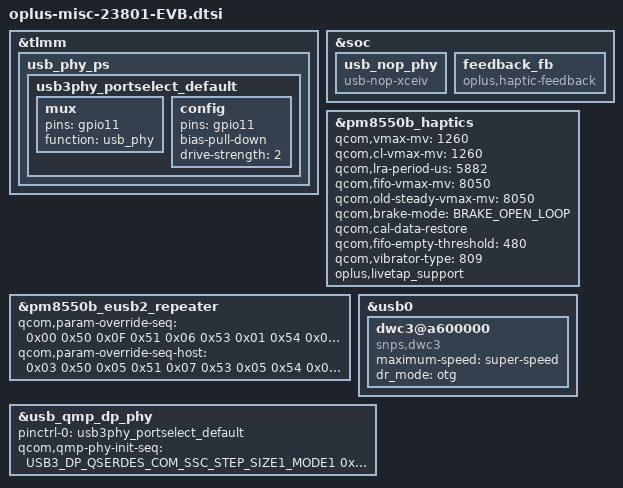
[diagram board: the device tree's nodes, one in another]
#include <dt-bindings/phy/qcom,usb3-4nm-qmp-combo.h>

&tlmm {
	usb_phy_ps: usb_phy_ps {
		usb3phy_portselect_default: usb3phy_portselect_default {
			mux {
				pins = "gpio11";
				function = "usb_phy";
			};

			config {
				pins = "gpio11";
				bias-pull-down;
				drive-strength = <2>;
			};
		};
	};
};

&soc {
	usb_nop_phy: usb_nop_phy {
		compatible = "usb-nop-xceiv";
	};
};

&pm8550b_haptics {
	qcom,vmax-mv = <1260>;
	qcom,cl-vmax-mv = <1260>;
	qcom,lra-period-us = <5882>;
	qcom,fifo-vmax-mv = <8050>;
	qcom,old-steady-vmax-mv = <8050>;
	qcom,brake-mode = <BRAKE_OPEN_LOOP>;
	qcom,cal-data-restore;
	qcom,fifo-empty-threshold = <480>;
	qcom,vibrator-type = <809>;//0809
	oplus,livetap_support;
};

&pm8550b_eusb2_repeater {
	qcom,param-override-seq = <0x00 0x50 0x0F 0x51 0x06 0x53 0x01 0x54
			0x03 0x55 0x00 0x56 0x07 0x57 0x2 0x58 0x3 0x59 0x1 0x5A 0x2 0x5B>;
	qcom,param-override-seq-host = <0x03 0x50 0x05 0x51 0x07 0x53 0x05 0x54
			0x01 0x55 0x00 0x56 0x02 0x57 0x2 0x58 0x3 0x59 0x1 0x5A 0x2 0x5B>;
};

&usb0 {
	dwc3@a600000 {
		compatible = "snps,dwc3";
		maximum-speed = "super-speed";
		dr_mode = "otg";
	};
};

&usb_qmp_dp_phy {
	pinctrl-names = "default";
	pinctrl-0 = <&usb3phy_portselect_default>;
	qcom,qmp-phy-init-seq =
		/* <reg_offset, value> */
		<USB3_DP_QSERDES_COM_SSC_STEP_SIZE1_MODE1 0xC0
		USB3_DP_QSERDES_COM_SSC_STEP_SIZE2_MODE1 0x01
		USB3_DP_QSERDES_COM_CP_CTRL_MODE1 0x02
		0x220c 0x3F
		0x260c 0x3F
		USB3_DP_QSERDES_COM_PLL_RCTRL_MODE1 0x16
		USB3_DP_QSERDES_COM_PLL_CCTRL_MODE1 0x36
		USB3_DP_QSERDES_COM_CORECLK_DIV_MODE1 0x04
		USB3_DP_QSERDES_COM_LOCK_CMP1_MODE1 0x16
		USB3_DP_QSERDES_COM_LOCK_CMP2_MODE1 0x41
		USB3_DP_QSERDES_COM_DEC_START_MODE1 0x41
		USB3_DP_QSERDES_COM_DEC_START_MSB_MODE1 0x00
		USB3_DP_QSERDES_COM_DIV_FRAC_START1_MODE1 0x55
		USB3_DP_QSERDES_COM_DIV_FRAC_START2_MODE1 0x75
		USB3_DP_QSERDES_COM_DIV_FRAC_START3_MODE1 0x01
		USB3_DP_QSERDES_COM_HSCLK_SEL_1 0x01
		USB3_DP_QSERDES_COM_VCO_TUNE1_MODE1 0x25
		USB3_DP_QSERDES_COM_VCO_TUNE2_MODE1 0x02
		USB3_DP_QSERDES_COM_BIN_VCOCAL_CMP_CODE1_MODE1 0x5C
		USB3_DP_QSERDES_COM_BIN_VCOCAL_CMP_CODE2_MODE1 0x0F
		USB3_DP_QSERDES_COM_BIN_VCOCAL_CMP_CODE1_MODE0 0x5C
		USB3_DP_QSERDES_COM_BIN_VCOCAL_CMP_CODE2_MODE0 0x0F
		USB3_DP_QSERDES_COM_SSC_STEP_SIZE1_MODE0 0xC0
		USB3_DP_QSERDES_COM_SSC_STEP_SIZE2_MODE0 0x01
		USB3_DP_QSERDES_COM_CP_CTRL_MODE0 0x02
		USB3_DP_QSERDES_COM_PLL_RCTRL_MODE0 0x16
		USB3_DP_QSERDES_COM_PLL_CCTRL_MODE0 0x36
		USB3_DP_QSERDES_COM_LOCK_CMP1_MODE0 0x08
		USB3_DP_QSERDES_COM_LOCK_CMP2_MODE0 0x1A
		USB3_DP_QSERDES_COM_DEC_START_MODE0 0x41
		USB3_DP_QSERDES_COM_DEC_START_MSB_MODE0 0x00
		USB3_DP_QSERDES_COM_DIV_FRAC_START1_MODE0 0x55
		USB3_DP_QSERDES_COM_DIV_FRAC_START2_MODE0 0x75
		USB3_DP_QSERDES_COM_DIV_FRAC_START3_MODE0 0x01
		USB3_DP_QSERDES_COM_VCO_TUNE1_MODE0 0x25
		USB3_DP_QSERDES_COM_VCO_TUNE2_MODE0 0x02
		USB3_DP_QSERDES_COM_BG_TIMER 0x0A
		USB3_DP_QSERDES_COM_SSC_EN_CENTER 0x01
		USB3_DP_QSERDES_COM_SSC_PER1 0x62
		USB3_DP_QSERDES_COM_SSC_PER2 0x02
		USB3_DP_QSERDES_COM_SYSCLK_BUF_ENABLE 0x0C
		USB3_DP_QSERDES_COM_SYSCLK_EN_SEL 0x1A
		USB3_DP_QSERDES_COM_LOCK_CMP_CFG 0x14
		USB3_DP_QSERDES_COM_VCO_TUNE_MAP 0x04
		USB3_DP_QSERDES_COM_CORE_CLK_EN 0x20
		USB3_DP_QSERDES_COM_CMN_CONFIG_1 0x16
		USB3_DP_QSERDES_COM_AUTO_GAIN_ADJ_CTRL_1 0xB6
		USB3_DP_QSERDES_COM_AUTO_GAIN_ADJ_CTRL_2 0x4B
		USB3_DP_QSERDES_COM_AUTO_GAIN_ADJ_CTRL_3 0x37
		USB3_DP_QSERDES_COM_ADDITIONAL_MISC 0x0C
		USB3_DP_QSERDES_TXA_RES_CODE_LANE_TX 0x00
		USB3_DP_QSERDES_TXA_RES_CODE_LANE_RX 0x00
		USB3_DP_QSERDES_TXA_RES_CODE_LANE_OFFSET_TX 0x1F
		USB3_DP_QSERDES_TXA_RES_CODE_LANE_OFFSET_RX 0x09
		USB3_DP_QSERDES_TXA_LANE_MODE_1 0xF5
		USB3_DP_QSERDES_TXA_LANE_MODE_3 0x3F
		USB3_DP_QSERDES_TXA_LANE_MODE_4 0x3F
		USB3_DP_QSERDES_TXA_LANE_MODE_5 0x5F
		USB3_DP_QSERDES_TXA_RCV_DETECT_LVL_2 0x12
		USB3_DP_QSERDES_TXA_PI_QEC_CTRL 0x21
		USB3_DP_QSERDES_RXA_UCDR_FO_GAIN 0x0A
		USB3_DP_QSERDES_RXA_UCDR_SO_GAIN 0x06
		USB3_DP_QSERDES_RXA_UCDR_FASTLOCK_FO_GAIN 0x2F
		USB3_DP_QSERDES_RXA_UCDR_SO_SATURATION_AND_ENABLE 0x7F
		USB3_DP_QSERDES_RXA_UCDR_FASTLOCK_COUNT_LOW 0xFF
		USB3_DP_QSERDES_RXA_UCDR_FASTLOCK_COUNT_HIGH 0x0F
		USB3_DP_QSERDES_RXA_UCDR_PI_CONTROLS 0x99
		USB3_DP_QSERDES_RXA_UCDR_SB2_THRESH1 0x08
		USB3_DP_QSERDES_RXA_UCDR_SB2_THRESH2 0x08
		USB3_DP_QSERDES_RXA_UCDR_SB2_GAIN1 0x00
		USB3_DP_QSERDES_RXA_UCDR_SB2_GAIN2 0x0A
		USB3_DP_QSERDES_RXA_AUX_DATA_TCOARSE_TFINE 0xA0
		USB3_DP_QSERDES_RXA_VGA_CAL_CNTRL1 0x54
		USB3_DP_QSERDES_RXA_VGA_CAL_CNTRL2 0x0F
		USB3_DP_QSERDES_RXA_GM_CAL 0x13
		USB3_DP_QSERDES_RXA_RX_EQU_ADAPTOR_CNTRL2 0x0F
		USB3_DP_QSERDES_RXA_RX_EQU_ADAPTOR_CNTRL3 0x4A
		USB3_DP_QSERDES_RXA_RX_EQU_ADAPTOR_CNTRL4 0x0A
		USB3_DP_QSERDES_RXA_RX_IDAC_TSETTLE_LOW 0x07
		USB3_DP_QSERDES_RXA_RX_IDAC_TSETTLE_HIGH 0x00
		USB3_DP_QSERDES_RXA_RX_EQ_OFFSET_ADAPTOR_CNTRL1 0x47
		USB3_DP_QSERDES_RXA_SIGDET_CNTRL 0x04
		USB3_DP_QSERDES_RXA_SIGDET_DEGLITCH_CNTRL 0x0E
		USB3_DP_QSERDES_RXA_RX_MODE_00_LOW 0x3F
		USB3_DP_QSERDES_RXA_RX_MODE_00_HIGH 0xBF
		USB3_DP_QSERDES_RXA_RX_MODE_00_HIGH2 0xFF
		USB3_DP_QSERDES_RXA_RX_MODE_00_HIGH3 0xDF
		USB3_DP_QSERDES_RXA_RX_MODE_00_HIGH4 0xED
		USB3_DP_QSERDES_RXA_RX_MODE_01_LOW 0xDC
		USB3_DP_QSERDES_RXA_RX_MODE_01_HIGH 0x5C
		USB3_DP_QSERDES_RXA_RX_MODE_01_HIGH2 0x9C
		USB3_DP_QSERDES_RXA_RX_MODE_01_HIGH3 0x1D
		USB3_DP_QSERDES_RXA_RX_MODE_01_HIGH4 0x09
		USB3_DP_QSERDES_RXA_DFE_EN_TIMER 0x04
		USB3_DP_QSERDES_RXA_DFE_CTLE_POST_CAL_OFFSET 0x38
		USB3_DP_QSERDES_RXA_DCC_CTRL1 0x0C
		USB3_DP_QSERDES_RXA_VTH_CODE 0x10
		USB3_DP_QSERDES_RXA_SIGDET_CAL_CTRL1 0x14
		USB3_DP_QSERDES_RXA_SIGDET_CAL_TRIM 0x08
		USB3_DP_QSERDES_TXB_RES_CODE_LANE_TX 0x00
		USB3_DP_QSERDES_TXB_RES_CODE_LANE_RX 0x00
		USB3_DP_QSERDES_TXB_RES_CODE_LANE_OFFSET_TX 0x1F
		USB3_DP_QSERDES_TXB_RES_CODE_LANE_OFFSET_RX 0x09
		USB3_DP_QSERDES_TXB_LANE_MODE_1 0xF5
		USB3_DP_QSERDES_TXB_LANE_MODE_3 0x3F
		USB3_DP_QSERDES_TXB_LANE_MODE_4 0x3F
		USB3_DP_QSERDES_TXB_LANE_MODE_5 0x5F
		USB3_DP_QSERDES_TXB_RCV_DETECT_LVL_2 0x12
		USB3_DP_QSERDES_TXB_PI_QEC_CTRL 0x05
		USB3_DP_QSERDES_RXB_UCDR_FO_GAIN 0x0A
		USB3_DP_QSERDES_RXB_UCDR_SO_GAIN 0x06
		USB3_DP_QSERDES_RXB_UCDR_FASTLOCK_FO_GAIN 0x2F
		USB3_DP_QSERDES_RXB_UCDR_SO_SATURATION_AND_ENABLE 0x7F
		USB3_DP_QSERDES_RXB_UCDR_FASTLOCK_COUNT_LOW 0xFF
		USB3_DP_QSERDES_RXB_UCDR_FASTLOCK_COUNT_HIGH 0x0F
		USB3_DP_QSERDES_RXB_UCDR_PI_CONTROLS 0x99
		USB3_DP_QSERDES_RXB_UCDR_SB2_THRESH1 0x08
		USB3_DP_QSERDES_RXB_UCDR_SB2_THRESH2 0x08
		USB3_DP_QSERDES_RXB_UCDR_SB2_GAIN1 0x00
		USB3_DP_QSERDES_RXB_UCDR_SB2_GAIN2 0x0A
		USB3_DP_QSERDES_RXB_AUX_DATA_TCOARSE_TFINE 0xA0
		USB3_DP_QSERDES_RXB_VGA_CAL_CNTRL1 0x54
		USB3_DP_QSERDES_RXB_VGA_CAL_CNTRL2 0x0F
		USB3_DP_QSERDES_RXB_GM_CAL 0x13
		USB3_DP_QSERDES_RXB_RX_EQU_ADAPTOR_CNTRL2 0x0F
		USB3_DP_QSERDES_RXB_RX_EQU_ADAPTOR_CNTRL3 0x4A
		USB3_DP_QSERDES_RXB_RX_EQU_ADAPTOR_CNTRL4 0x0A
		USB3_DP_QSERDES_RXB_RX_IDAC_TSETTLE_LOW 0x07
		USB3_DP_QSERDES_RXB_RX_IDAC_TSETTLE_HIGH 0x00
		USB3_DP_QSERDES_RXB_RX_EQ_OFFSET_ADAPTOR_CNTRL1 0x47
		USB3_DP_QSERDES_RXB_SIGDET_CNTRL 0x04
		USB3_DP_QSERDES_RXB_SIGDET_DEGLITCH_CNTRL 0x0E
		USB3_DP_QSERDES_RXB_RX_MODE_00_LOW 0xBF
		USB3_DP_QSERDES_RXB_RX_MODE_00_HIGH 0xBF
		USB3_DP_QSERDES_RXB_RX_MODE_00_HIGH2 0xBF
		USB3_DP_QSERDES_RXB_RX_MODE_00_HIGH3 0xDF
		USB3_DP_QSERDES_RXB_RX_MODE_00_HIGH4 0xFD
		USB3_DP_QSERDES_RXB_RX_MODE_01_LOW 0xDC
		USB3_DP_QSERDES_RXB_RX_MODE_01_HIGH 0x5C
		USB3_DP_QSERDES_RXB_RX_MODE_01_HIGH2 0x9C
		USB3_DP_QSERDES_RXB_RX_MODE_01_HIGH3 0x1D
		USB3_DP_QSERDES_RXB_RX_MODE_01_HIGH4 0x09
		USB3_DP_QSERDES_RXB_DFE_EN_TIMER 0x04
		USB3_DP_QSERDES_RXB_DFE_CTLE_POST_CAL_OFFSET 0x38
		USB3_DP_QSERDES_RXB_DCC_CTRL1 0x0C
		USB3_DP_QSERDES_RXB_VTH_CODE 0x10
		USB3_DP_QSERDES_RXB_SIGDET_CAL_CTRL1 0x14
		USB3_DP_QSERDES_RXB_SIGDET_CAL_TRIM 0x08
		USB3_DP_PCS_LOCK_DETECT_CONFIG1 0xC4
		USB3_DP_PCS_LOCK_DETECT_CONFIG2 0x89
		USB3_DP_PCS_LOCK_DETECT_CONFIG3 0x20
		USB3_DP_PCS_LOCK_DETECT_CONFIG6 0x13
		USB3_DP_PCS_REFGEN_REQ_CONFIG1 0x21
		USB3_DP_PCS_RX_SIGDET_LVL 0x99
		USB3_DP_PCS_RCVR_DTCT_DLY_P1U2_L 0xE7
		USB3_DP_PCS_RCVR_DTCT_DLY_P1U2_H 0x03
		USB3_DP_PCS_CDR_RESET_TIME 0x0A
		USB3_DP_PCS_ALIGN_DETECT_CONFIG1 0x88
		USB3_DP_PCS_ALIGN_DETECT_CONFIG2 0x13
		USB3_DP_PCS_PCS_TX_RX_CONFIG 0x0C
		USB3_DP_PCS_EQ_CONFIG1 0x4B
		USB3_DP_PCS_EQ_CONFIG5 0x10
		USB3_DP_PCS_USB3_POWER_STATE_CONFIG1 0x68
		USB3_DP_PCS_USB3_LFPS_DET_HIGH_COUNT_VAL 0xF8
		USB3_DP_PCS_USB3_RXEQTRAINING_DFE_TIME_S2 0x07
		USB3_DP_PCS_USB3_RCVR_DTCT_DLY_U3_L 0x40
		USB3_DP_PCS_USB3_RCVR_DTCT_DLY_U3_H 0x00>;
};

&soc {
	feedback_fb: feedback_fb {
		compatible = "oplus,haptic-feedback";
	};
};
